# STM32L0x2 register map
File version: 1.7
CPU: CM0+ r0p0, little endian, MPU, no FPU, 2 interrupt priority bits
Registers are 32-bit, read-write, reset 0x0 unless marked. A register's access mark holds for its fields unless they carry their own. Offsets are from the block's base; [hi:lo] are bit positions; {n}, {i} and the like mark numbered series; 'fields as' and 'values as' point back to an identical list.

## TIM21 — General-purpose-timers
Base 0x40010800
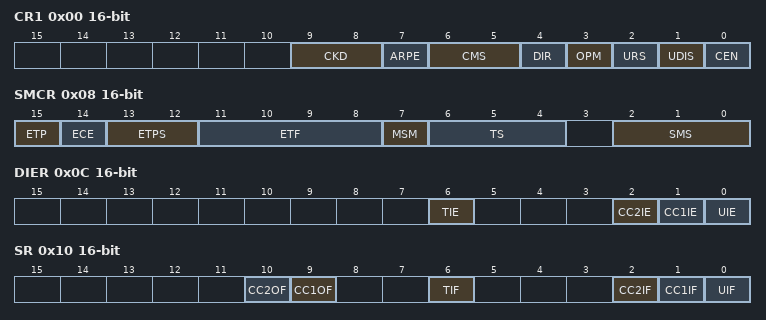
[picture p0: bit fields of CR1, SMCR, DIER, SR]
0x00 CR1 16-bit — control register 1
  [9:8] CKD — Clock division
    0=Div1 (t_DTS = t_CK_INT); 1=Div2 (t_DTS = 2 × t_CK_INT); 2=Div4 (t_DTS = 4 × t_CK_INT)
  [7] ARPE — Auto-reload preload enable
    0=Disabled (TIMx_APRR register is not buffered); 1=Enabled (TIMx_APRR register is buffered)
  [6:5] CMS — Center-aligned mode selection
    0=EdgeAligned (The counter counts up or down depending on the direction bit); 1=CenterAligned1 (The counter counts up and down alternatively. Output compare interrupt flags are set only when the counter is counting down.); 2=CenterAligned2 (The counter counts up and down alternatively. Output compare interrupt flags are set only when the counter is counting up.); 3=CenterAligned3 (The counter counts up and down alternatively. Output compare interrupt flags are set both when the counter is counting up or down.)
  [4] DIR — Direction
    0=Up (Counter used as upcounter); 1=Down (Counter used as downcounter)
  [3] OPM — One-pulse mode
    0=Disabled (Counter is not stopped at update event); 1=Enabled (Counter stops counting at the next update event (clearing the CEN bit))
  [2] URS — Update request source
    0=AnyEvent (Any of counter overflow/underflow, setting UG, or update through slave mode, generates an update interrupt or DMA request); 1=CounterOnly (Only counter overflow/underflow generates an update interrupt or DMA request)
  [1] UDIS — Update disable
    0=Enabled (Update event enabled); 1=Disabled (Update event disabled)
  [0] CEN — Counter enable
    0=Disabled (Counter disabled); 1=Enabled (Counter enabled)
0x04 CR2 16-bit — control register 2
  [6:4] MMS — Master mode selection
    0=Reset - the UG bit from the TIMx_EGR register is used as trigger output (TRGO); 1=Enable - the Counter enable signal, CNT_EN, is used as trigger output (TRGO); 2=Update - The update event is selected as trigger output (TRGO); 3=Compare Pulse - The trigger output send a positive pulse when the CC1IF flag is to be set (even if it was already high), as soon as a capture or a compare match occurred; 4=OC1REF (OC1REF signal is used as trigger output (TRGO)); 5=OC2REF (OC2REF signal is used as trigger output (TRGO))
0x08 SMCR 16-bit — slave mode control register
  [15] ETP — External trigger polarity
    0=RisingEdge (ETR is non-inverted, active at high level or rising edge); 1=FallingEdge (ETR is inverted, active at low level or falling edge)
  [14] ECE — External clock enable
    0=Disabled (External clock mode 2 disabled); 1=Enabled (External clock mode 2 enabled)
  [13:12] ETPS — External trigger prescaler
    0=Div1 (Prescaler OFF); 1=Div2 (ETRP frequency divided by 2); 2=Div4 (ETRP frequency divided by 4); 3=Div8 (ETRP frequency divided by 8)
  [11:8] ETF — External trigger filter
    0=No filter, sampling is done at fDTS; 1=FCK_INT_N2 (fSAMPLING=fCK_INT, N=2); 2=FCK_INT_N4 (fSAMPLING=fCK_INT, N=4); 3=FCK_INT_N8 (fSAMPLING=fCK_INT, N=8); 4=FDTS_Div2_N6 (fSAMPLING=fDTS/2, N=6); 5=FDTS_Div2_N8 (fSAMPLING=fDTS/2, N=8); 6=FDTS_Div4_N6 (fSAMPLING=fDTS/4, N=6); 7=FDTS_Div4_N8 (fSAMPLING=fDTS/4, N=8); 8=FDTS_Div8_N6 (fSAMPLING=fDTS/8, N=6); 9=FDTS_Div8_N8 (fSAMPLING=fDTS/8, N=8); 10=FDTS_Div16_N5 (fSAMPLING=fDTS/16, N=5); 11=FDTS_Div16_N6 (fSAMPLING=fDTS/16, N=6); 12=FDTS_Div16_N8 (fSAMPLING=fDTS/16, N=8); 13=FDTS_Div32_N5 (fSAMPLING=fDTS/32, N=5); 14=FDTS_Div32_N6 (fSAMPLING=fDTS/32, N=6); 15=FDTS_Div32_N8 (fSAMPLING=fDTS/32, N=8)
  [7] MSM — Master/Slave mode
    0=NoSync (No action); 1=Sync (The effect of an event on the trigger input (TRGI) is delayed to allow a perfect synchronization between the current timer and its slaves (through TRGO). It is useful if we want to synchronize several timers on a single external event.)
  [6:4] TS — Trigger selection
    0=ITR0 (Internal Trigger 0 (ITR0)); 1=ITR1 (Internal Trigger 1 (ITR1)); 2=ITR2 (Internal Trigger 2 (ITR2)); 4=TI1F_ED (TI1 Edge Detector (TI1F_ED)); 5=TI1FP1 (Filtered Timer Input 1 (TI1FP1)); 6=TI2FP2 (Filtered Timer Input 2 (TI2FP2)); 7=ETRF (External Trigger input (ETRF))
  [2:0] SMS — Slave mode selection
    0=Disabled (Slave mode disabled - if CEN = ‘1 then the prescaler is clocked directly by the internal clock.); 1=Encoder mode 1 - Counter counts up/down on TI2FP1 edge depending on TI1FP2 level; 2=Encoder mode 2 - Counter counts up/down on TI1FP2 edge depending on TI2FP1 level; 3=Encoder mode 3 - Counter counts up/down on both TI1FP1 and TI2FP2 edges depending on the level of the other input; 4=Reset Mode - Rising edge of the selected trigger input (TRGI) reinitializes the counter and generates an update of the registers; 5=Gated Mode - The counter clock is enabled when the trigger input (TRGI) is high. The counter stops (but is not reset) as soon as the trigger becomes low. Both start and stop of the counter are controlled.; 6=Trigger Mode - The counter starts at a rising edge of the trigger TRGI (but it is not reset). Only the start of the counter is controlled.; 7=Ext_Clock_Mode (External Clock Mode 1 - Rising edges of the selected trigger (TRGI) clock the counter.)
0x0C DIER 16-bit — DMA/Interrupt enable register
  [6] TIE — Trigger interrupt enable
    0=Disabled (Trigger interrupt disabled); 1=Enabled (Trigger interrupt enabled)
  [n] CC{n}IE (n=1..2) — Capture/Compare {n} interrupt enable
    0=Disabled (CCx interrupt disabled); 1=Enabled (CCx interrupt enabled)
  [0] UIE — Update interrupt enable
    0=Disabled (Update interrupt disabled); 1=Enabled (Update interrupt enabled)
0x10 SR 16-bit — status register
  [n+8] CC{n}OF (n=1..2) write-0-clears — Capture/Compare {n} overcapture flag
    on read: 0=No overcapture has been detected; 1=Overcapture (The counter value has been captured in TIMx_CCRx register while CCxIF flag was already set) | on write: 0=Clear flag
  [6] TIF write-0-clears — Trigger interrupt flag
    on read: 0=No trigger event occurred; 1=Trigger interrupt pending | on write: 0=Clear flag
  [n] CC{n}IF (n=1..2) write-0-clears — Capture/compare {n} interrupt flag
    on read: 0=NoMatch (No campture/compare has been detected); 1=Match (If CC1 is an output: The content of the counter TIMx_CNT matches the content of the TIMx_CCR1 register. If CC1 is an input: The counter value has been captured in TIMx_CCR1 register.) | on write: 0=Clear flag
  [0] UIF write-0-clears — Update interrupt flag
    on read: 0=NoUpdateOccurred; 1=UpdatePending (Update interrupt pending) | on write: 0=Clear flag
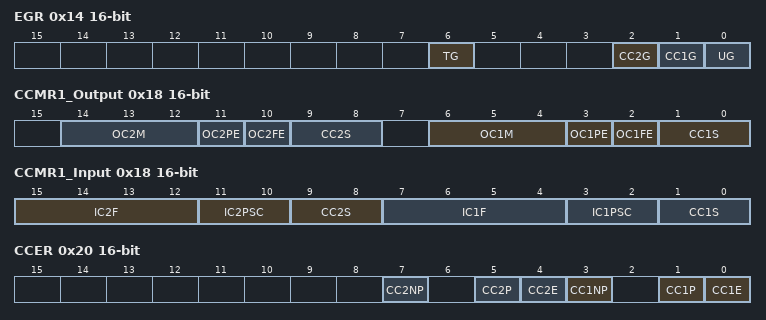
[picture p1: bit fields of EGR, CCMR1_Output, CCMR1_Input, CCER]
0x14 EGR 16-bit wo — event generation register
  [6] TG — Trigger generation
    1=Trigger (The TIF flag is set in TIMx_SR register. Related interrupt or DMA transfer can occur if enabled.)
  [n] CC{n}G (n=1..2) — Capture/compare {n} generation
    1=Trigger (If CC1 is an output: CC1IF flag is set, Corresponding interrupt or DMA request is sent if enabled. If CC1 is an input: The current value of the counter is captured in TIMx_CCR1 register.)
  [0] UG — Update generation
    1=Update (Re-initializes the timer counter and generates an update of the registers.)
0x18 CCMR1_Output 16-bit — capture/compare mode register (output mode)
  [8n-2:8n-4] OC{n}M (n=1..2) — Output compare {n} mode
    0=Frozen (The comparison between the output compare register TIMx_CCRy and the counter TIMx_CNT has no effect on the outputs); 1=ActiveOnMatch (Set channel to active level on match. OCyREF signal is forced high when the counter matches the capture/compare register); 2=InactiveOnMatch (Set channel to inactive level on match. OCyREF signal is forced low when the counter matches the capture/compare register); 3=Toggle (OCyREF toggles when TIMx_CNT=TIMx_CCRy); 4=ForceInactive (OCyREF is forced low); 5=ForceActive (OCyREF is forced high); 6=PwmMode1 (In upcounting, channel is active as long as TIMx_CNT<TIMx_CCRy else inactive. In downcounting, channel is inactive as long as TIMx_CNT>TIMx_CCRy else active); 7=PwmMode2 (Inversely to PwmMode1)
  [8n-5] OC{n}PE (n=1..2) — Output compare {n} preload enable
    0=Disabled (Preload register on CCRx disabled. New values written to CCRx are taken into account immediately); 1=Enabled (Preload register on CCRx enabled. Preload value is loaded into active register on each update event)
  [8n-6] OC{n}FE (n=1..2) — Output compare {n} fast enable
    0=Disabled (Fast output disabled); 1=Enabled (Fast output enabled)
  [8n-7:8n-8] CC{n}S (n=1..2) — Capture/Compare {n} selection
    0=Output (CCx channel is configured as output)
0x18 CCMR1_Input 16-bit (alternate view of CCMR1_Output) — capture/compare mode register 1 (input mode)
  [9:8] CC2S — Capture/Compare 2 selection
    1=TI2 (CC2 channel is configured as input, IC2 is mapped on TI2); 2=TI1 (CC2 channel is configured as input, IC2 is mapped on TI1); 3=TRC (CC2 channel is configured as input, IC2 is mapped on TRC)
  [8n-1:8n-4] IC{n}F (n=1..2) — Input capture {n} filter
    values as SMCR.ETF
  [8n-5:8n-6] IC{n}PSC (n=1..2) — Input capture {n} prescaler
    0=No prescaler, capture is done each time an edge is detected on the capture input; 1=TwoEvents (Capture is done once every 2 events); 2=FourEvents (Capture is done once every 4 events); 3=EightEvents (Capture is done once every 8 events)
  [1:0] CC1S — Capture/Compare 1 selection
    1=TI1 (CC1 channel is configured as input, IC1 is mapped on TI1); 2=TI2 (CC1 channel is configured as input, IC1 is mapped on TI2); 3=TRC (CC1 channel is configured as input, IC1 is mapped on TRC)
0x20 CCER 16-bit — capture/compare enable register
  [4n-1] CC{n}NP (n=1..2) — Capture/Compare {n} output Polarity
    0=Negative polarity; 1=Positive polarity
  [4n-3] CC{n}P (n=1..2) — Capture/Compare {n} output Polarity
    0=RisingEdge (Noninverted/rising edge); 1=FallingEdge (Inverted/falling edge)
  [4n-4] CC{n}E (n=1..2) — Capture/Compare {n} output enable
    0=Disabled (Capture disabled); 1=Enabled (Capture enabled)
0x24 CNT 16-bit — counter
  [15:0] CNT — counter value
0x28 PSC 16-bit — prescaler
  [15:0] PSC — Prescaler value
0x2C ARR 16-bit reset 0xFFFF — auto-reload register
  [15:0] ARR — Auto-reload value
{0x30+4i} CCR{i} (i=1..2) 16-bit — capture/compare register
  [15:0] CCR — Capture/Compare value
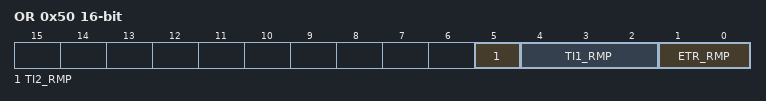
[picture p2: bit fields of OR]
0x50 OR 16-bit — TIM21 option register
  [5] TI2_RMP — Timer21 TI2
    0=GPIO (TIM2x TI2 input connected to GPIO); 1=COMP2_OUT (TIM2x TI2 input connected to COMP2_OUT)
  [4:2] TI1_RMP — Timer21 TI1
    0=GPIO (TIM2x TI1 input connected to GPIO); 1=COMP2_OUT (TIM2x TI1 input connected to COMP2_OUT); 2=COMP1_OUT (TIM2x TI1 input connected to COMP1_OUT)
  [1:0] ETR_RMP — Timer21 ETR remap
    0=GPIO (TIM2x ETR input connected to GPIO); 1=COMP2_OUT (TIM2x ETR input connected to COMP2_OUT); 2=COMP1_OUT (TIM2x ETR input connected to COMP1_OUT); 3=LSE (TIM2x ETR input connected to LSE clock)

## TIM22 — General-purpose-timers
Base 0x40011400
Registers as TIM21; these are added or differ:
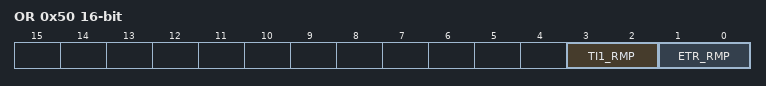
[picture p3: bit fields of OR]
0x50 OR 16-bit — TIM22 option register
  [3:2] TI1_RMP — Timer22 TI1
    0=GPIO (TIM2x TI1 input connected to GPIO); 1=COMP2_OUT (TIM2x TI1 input connected to COMP2_OUT); 2=COMP1_OUT (TIM2x TI1 input connected to COMP1_OUT)
  [1:0] ETR_RMP — Timer22 ETR remap
    0=GPIO (TIM2x ETR input connected to GPIO); 1=COMP2_OUT (TIM2x ETR input connected to COMP2_OUT); 2=COMP1_OUT (TIM2x ETR input connected to COMP1_OUT); 3=LSE (TIM2x ETR input connected to LSE clock)
